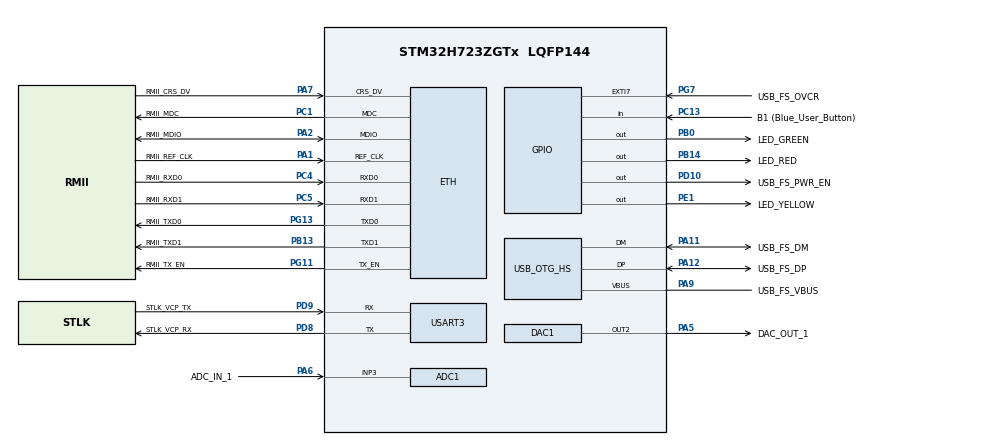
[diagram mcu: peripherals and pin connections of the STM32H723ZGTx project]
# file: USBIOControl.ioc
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ADC1.Channel-5\#ChannelRegularConversion=ADC_CHANNEL_3
ADC1.ClockPrescaler=ADC_CLOCK_ASYNC_DIV256
ADC1.ContinuousConvMode=ENABLE
ADC1.NbrOfConversion=1
ADC1.NbrOfConversionFlag=1
ADC1.OffsetNumber-5\#ChannelRegularConversion=ADC_OFFSET_NONE
ADC1.OffsetSignedSaturation-5\#ChannelRegularConversion=DISABLE
ADC1.Rank-5\#ChannelRegularConversion=1
ADC1.Resolution=ADC_RESOLUTION_12B
ADC1.SamplingTime-5\#ChannelRegularConversion=ADC_SAMPLETIME_1CYCLE_5
ADC1.master=1
DAC1.DAC_Channel-DAC_OUT2=DAC_CHANNEL_2
Dma.ADC1.0.Direction=DMA_PERIPH_TO_MEMORY
Dma.ADC1.0.EventEnable=DISABLE
Dma.ADC1.0.FIFOMode=DMA_FIFOMODE_DISABLE
Dma.ADC1.0.Instance=DMA1_Stream0
Dma.ADC1.0.MemDataAlignment=DMA_MDATAALIGN_HALFWORD
Dma.ADC1.0.MemInc=DMA_MINC_ENABLE
Dma.ADC1.0.Mode=DMA_CIRCULAR
Dma.ADC1.0.PeriphDataAlignment=DMA_PDATAALIGN_HALFWORD
Dma.ADC1.0.PeriphInc=DMA_PINC_DISABLE
Dma.ADC1.0.Polarity=HAL_DMAMUX_REQ_GEN_RISING
Dma.ADC1.0.Priority=DMA_PRIORITY_LOW
Dma.ADC1.0.RequestNumber=1
Dma.ADC1.0.SignalID=NONE
Dma.ADC1.0.SyncEnable=DISABLE
Dma.ADC1.0.SyncPolarity=HAL_DMAMUX_SYNC_NO_EVENT
Dma.ADC1.0.SyncRequestNumber=1
Dma.ADC1.0.SyncSignalID=NONE
Dma.Request0=ADC1
ETH.MediaInterface=HAL_ETH_RMII_MODE
Mcu.Family=STM32H7
Mcu.Name=STM32H723ZGTx
Mcu.Package=LQFP144
NVIC.DMA1_Stream0_IRQn=true\:0\:0\:false\:false\:true\:false\:true
NVIC.OTG_HS_IRQn=true\:0\:0\:false\:false\:true\:false\:true
NVIC.PriorityGroup=NVIC_PRIORITYGROUP_4
PA1.GPIO_Label=RMII_REF_CLK
PA1.Mode=RMII
PA1.Signal=ETH_REF_CLK
PA10.GPIO_Label=USB_FS_ID
PA10.Signal=USB_OTG_HS_ID
PA11.GPIO_Label=USB_FS_DM
PA11.Mode=Device_Only_FS
PA11.Signal=USB_OTG_HS_DM
PA12.GPIO_Label=USB_FS_DP
PA12.Mode=Device_Only_FS
PA12.Signal=USB_OTG_HS_DP
PA13(JTMS/SWDIO).GPIO_Label=SWDIO
PA13(JTMS/SWDIO).Mode=Trace_Asynchronous_SW
PA13(JTMS/SWDIO).Signal=DEBUG_JTMS-SWDIO
PA14(JTCK/SWCLK).GPIO_Label=SWCLK
PA14(JTCK/SWCLK).Mode=Trace_Asynchronous_SW
PA14(JTCK/SWCLK).Signal=DEBUG_JTCK-SWCLK
PA2.GPIO_Label=RMII_MDIO
PA2.Mode=RMII
PA2.Signal=ETH_MDIO
PA5.GPIO_Label=DAC_OUT_1
PA5.Signal=COMP_DAC12_group
PA6.GPIO_Label=ADC_IN_1
PA6.GPIO_Mode=GPIO_MODE_ANALOG
PA6.GPIO_PuPd=GPIO_NOPULL
PA6.Signal=ADCx_INP3
PA7.GPIO_Label=RMII_CRS_DV
PA7.Mode=RMII
PA7.Signal=ETH_CRS_DV
PA9.GPIO_Label=USB_FS_VBUS
PA9.Mode=Activate_VBUS_FS
PA9.Signal=USB_OTG_HS_VBUS
PB0.GPIO_Label=LED_GREEN
PB0.Signal=GPIO_Output
PB13.GPIO_Label=RMII_TXD1
PB13.Mode=RMII
PB13.Signal=ETH_TXD1
PB14.GPIO_Label=LED_RED
PB14.Signal=GPIO_Output
PB3(JTDO/TRACESWO).GPIO_Label=SWO
PB3(JTDO/TRACESWO).Mode=Trace_Asynchronous_SW
PB3(JTDO/TRACESWO).Signal=DEBUG_JTDO-SWO
PC1.GPIO_Label=RMII_MDC
PC1.Mode=RMII
PC1.Signal=ETH_MDC
PC13.GPIO_Label=B1 (Blue_User_Button)
PC13.Signal=GPIO_Input
PC14-OSC32_IN.Mode=LSE-External-Oscillator
PC14-OSC32_IN.Signal=RCC_OSC32_IN
PC15-OSC32_OUT.Mode=LSE-External-Oscillator
PC15-OSC32_OUT.Signal=RCC_OSC32_OUT
PC4.GPIO_Label=RMII_RXD0
PC4.Mode=RMII
PC4.Signal=ETH_RXD0
PC5.GPIO_Label=RMII_RXD1
PC5.Mode=RMII
PC5.Signal=ETH_RXD1
PD10.GPIO_Label=USB_FS_PWR_EN
PD10.Signal=GPIO_Output
PD8.GPIO_Label=STLK_VCP_RX
PD8.Mode=Asynchronous
PD8.Signal=USART3_TX
PD9.GPIO_Label=STLK_VCP_TX
PD9.Mode=Asynchronous
PD9.Signal=USART3_RX
PE1.GPIO_Label=LED_YELLOW
PE1.Signal=GPIO_Output
PG11.GPIO_Label=RMII_TX_EN
PG11.Mode=RMII
PG11.Signal=ETH_TX_EN
PG13.GPIO_Label=RMII_TXD0
PG13.Mode=RMII
PG13.Signal=ETH_TXD0
PG7.GPIO_Label=USB_FS_OVCR
PG7.Signal=GPXTI7
PH0-OSC_IN.GPIO_Label=MCO
PH0-OSC_IN.Mode=HSE-External-Clock-Source
PH0-OSC_IN.Signal=RCC_OSC_IN
PH1-OSC_OUT.Signal=RCC_OSC_OUT
ProjectManager.HeapSize=0x200
ProjectManager.StackSize=0x400
ProjectManager.TargetToolchain=STM32CubeIDE
RCC.ADCFreq_Value=96000000
RCC.APB1Freq_Value=137500000
RCC.APB2Freq_Value=137500000
RCC.APB3Freq_Value=137500000
RCC.APB4Freq_Value=137500000
RCC.CortexFreq_Value=550000000
RCC.D1PPRE=RCC_APB3_DIV2
RCC.D2PPRE1=RCC_APB1_DIV2
RCC.D2PPRE2=RCC_APB2_DIV2
RCC.D3PPRE=RCC_APB4_DIV2
RCC.DIVM1=4
RCC.DIVM2=1
RCC.DIVN1=275
RCC.DIVN2=24
RCC.DIVP1=1
RCC.DIVQ1=4
RCC.HCLKFreq_Value=275000000
RCC.HPRE=RCC_HCLK_DIV2
RCC.HSE_VALUE=8000000
RCC.PLLFRACN=0
RCC.PLLSourceVirtual=RCC_PLLSOURCE_HSE
RCC.SYSCLKFreq_VALUE=550000000
RCC.SYSCLKSource=RCC_SYSCLKSOURCE_PLLCLK
RCC.USBCLockSelection=RCC_USBCLKSOURCE_HSI48
RCC.USBFreq_Value=48000000
SH.ADCx_INP3.0=ADC1_INP3,IN3-Single-Ended
SH.COMP_DAC12_group.0=DAC1_OUT2,DAC_OUT2
USART3.VirtualMode-Asynchronous=VM_ASYNC
USB_DEVICE.CLASS_NAME_HS=CDC
USB_DEVICE.VirtualMode=Cdc
USB_DEVICE.VirtualModeHS=Cdc_HS
USB_OTG_HS.VirtualMode-Device_Only_FS=Device_Only_FS
VP_USB_DEVICE_VS_USB_DEVICE_CDC_HS.Mode=CDC_HS
board=NUCLEO-H723ZG

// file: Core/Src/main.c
/* USER CODE BEGIN Header */
/**
  ******************************************************************************
  * @file           : main.c
  * @brief          : Main program body
  ******************************************************************************
  * @attention
  *
  * Copyright (c) 2024 STMicroelectronics.
  * All rights reserved.
  *
  * This software is licensed under terms that can be found in the LICENSE file
  * in the root directory of this software component.
  * If no LICENSE file comes with this software, it is provided AS-IS.
  *
  ******************************************************************************
  */
/* USER CODE END Header */
#include "main.h"
#include "string.h"
#include "usb_device.h"

/* USER CODE BEGIN Includes */
#include "usbd_cdc_if.h"
#include <strings.h>
/* USER CODE END Includes */

#if defined ( __ICCARM__ ) /*!< IAR Compiler */

#pragma location=0x30000000
ETH_DMADescTypeDef  DMARxDscrTab[ETH_RX_DESC_CNT]; /* Ethernet Rx DMA Descriptors */
#pragma location=0x30000060
ETH_DMADescTypeDef  DMATxDscrTab[ETH_TX_DESC_CNT]; /* Ethernet Tx DMA Descriptors */
#pragma location=0x300000c0
uint8_t Rx_Buff[ETH_RX_DESC_CNT][ETH_MAX_PACKET_SIZE]; /* Ethernet Receive Buffers */

#elif defined ( __CC_ARM )  /* MDK ARM Compiler */

__attribute__((at(0x30000000))) ETH_DMADescTypeDef  DMARxDscrTab[ETH_RX_DESC_CNT]; /* Ethernet Rx DMA Descriptors */
__attribute__((at(0x30000060))) ETH_DMADescTypeDef  DMATxDscrTab[ETH_TX_DESC_CNT]; /* Ethernet Tx DMA Descriptors */
__attribute__((at(0x300000c0))) uint8_t Rx_Buff[ETH_RX_DESC_CNT][ETH_MAX_PACKET_SIZE]; /* Ethernet Receive Buffer */

#elif defined ( __GNUC__ ) /* GNU Compiler */

ETH_DMADescTypeDef DMARxDscrTab[ETH_RX_DESC_CNT] __attribute__((section(".RxDecripSection"))); /* Ethernet Rx DMA Descriptors */
ETH_DMADescTypeDef DMATxDscrTab[ETH_TX_DESC_CNT] __attribute__((section(".TxDecripSection")));   /* Ethernet Tx DMA Descriptors */
uint8_t Rx_Buff[ETH_RX_DESC_CNT][ETH_MAX_PACKET_SIZE] __attribute__((section(".RxArraySection"))); /* Ethernet Receive Buffers */

#endif

ETH_TxPacketConfig TxConfig;
ADC_HandleTypeDef hadc1;
DMA_HandleTypeDef hdma_adc1;

DAC_HandleTypeDef hdac1;

ETH_HandleTypeDef heth;

UART_HandleTypeDef huart3;

/* USER CODE BEGIN PV */
uint32_t value_adc;
uint32_t value_dac=0;
/* USER CODE END PV */

void SystemClock_Config(void);
static void MX_GPIO_Init(void);
static void MX_ETH_Init(void);
static void MX_USART3_UART_Init(void);
static void MX_DMA_Init(void);
static void MX_ADC1_Init(void);
static void MX_DAC1_Init(void);

/* USER CODE BEGIN 0 */
uint8_t data[6];
uint8_t buffer[64];
/* USER CODE END 0 */

int main(void)
{

  /* MCU Configuration--------------------------------------------------------*/

  /* Reset of all peripherals, Initializes the Flash interface and the Systick. */
  HAL_Init();

  /* Configure the system clock */
  SystemClock_Config();

  /* Initialize all configured peripherals */
  MX_GPIO_Init();
  MX_ETH_Init();
  MX_USART3_UART_Init();
  MX_DMA_Init();
  MX_ADC1_Init();
  MX_DAC1_Init();
  MX_USB_DEVICE_Init();
  /* USER CODE BEGIN 2 */

  HAL_DAC_Start(&hdac1,DAC_CHANNEL_2);
  HAL_ADCEx_Calibration_Start(&hadc1, ADC_CALIB_OFFSET_LINEARITY, ADC_SINGLE_ENDED);
  HAL_ADC_Start_DMA(&hadc1,(uint32_t*)&value_adc,1);
  /* USER CODE END 2 */

	data[0] = 0;
	data[1] = 0;
	data[2] = 0;
	data[3] = 0;
	data[4] = 0;
	data[5] = 10;

  /* Infinite loop */
  while (1)
  {
		HAL_GPIO_TogglePin(LED_GREEN_GPIO_Port, LED_GREEN_Pin);

		value_adc+=10;
itoa(value_adc, (char *) &data[0], 10);
		CDC_Transmit_HS(&data[0], sizeof(data));

		if(buffer[0]==1)
		{
			if(buffer[2] & (1u << 0))
			{
				HAL_GPIO_WritePin(LED_YELLOW_GPIO_Port, LED_YELLOW_Pin, GPIO_PIN_SET);
			}
			else
			{
				HAL_GPIO_WritePin(LED_YELLOW_GPIO_Port, LED_YELLOW_Pin, GPIO_PIN_RESET);
			}
			if(buffer[1] & (1u << 0))
			{
				HAL_GPIO_WritePin(LED_RED_GPIO_Port, LED_RED_Pin, GPIO_PIN_SET);
			}
			else
			{
				HAL_GPIO_WritePin(LED_RED_GPIO_Port, LED_RED_Pin, GPIO_PIN_RESET);
			}
//			value_dac = buffer[3]*10;
//			HAL_DAC_SetValue(&hdac1, DAC_CHANNEL_2, DAC_ALIGN_12B_R, value_dac);
		}

		HAL_DAC_SetValue(&hdac1, DAC_CHANNEL_2, DAC_ALIGN_12B_R, value_dac);

	  value_dac+=10;
	  if(value_dac>4095) {
		value_dac=0;
	  }

	  HAL_ADC_Start(&hadc1);
	  HAL_Delay(1000);
  }
}

void SystemClock_Config(void)
{
  RCC_OscInitTypeDef RCC_OscInitStruct = {0};
  RCC_ClkInitTypeDef RCC_ClkInitStruct = {0};

  /** Supply configuration update enable
  */
  HAL_PWREx_ConfigSupply(PWR_LDO_SUPPLY);
  /** Configure the main internal regulator output voltage
  */
  __HAL_PWR_VOLTAGESCALING_CONFIG(PWR_REGULATOR_VOLTAGE_SCALE0);

  while(!__HAL_PWR_GET_FLAG(PWR_FLAG_VOSRDY)) {}
  /** Macro to configure the PLL clock source
  */
  __HAL_RCC_PLL_PLLSOURCE_CONFIG(RCC_PLLSOURCE_HSE);
  /** Initializes the RCC Oscillators according to the specified parameters
  * in the RCC_OscInitTypeDef structure.
  */
  RCC_OscInitStruct.OscillatorType = RCC_OSCILLATORTYPE_HSI48|RCC_OSCILLATORTYPE_HSE;
  RCC_OscInitStruct.HSEState = RCC_HSE_BYPASS;
  RCC_OscInitStruct.HSI48State = RCC_HSI48_ON;
  RCC_OscInitStruct.PLL.PLLState = RCC_PLL_ON;
  RCC_OscInitStruct.PLL.PLLSource = RCC_PLLSOURCE_HSE;
  RCC_OscInitStruct.PLL.PLLM = 4;
  RCC_OscInitStruct.PLL.PLLN = 275;
  RCC_OscInitStruct.PLL.PLLP = 1;
  RCC_OscInitStruct.PLL.PLLQ = 4;
  RCC_OscInitStruct.PLL.PLLR = 2;
  RCC_OscInitStruct.PLL.PLLRGE = RCC_PLL1VCIRANGE_1;
  RCC_OscInitStruct.PLL.PLLVCOSEL = RCC_PLL1VCOWIDE;
  RCC_OscInitStruct.PLL.PLLFRACN = 0;
  if (HAL_RCC_OscConfig(&RCC_OscInitStruct) != HAL_OK)
  {
    Error_Handler();
  }
  /** Initializes the CPU, AHB and APB buses clocks
  */
  RCC_ClkInitStruct.ClockType = RCC_CLOCKTYPE_HCLK|RCC_CLOCKTYPE_SYSCLK
                              |RCC_CLOCKTYPE_PCLK1|RCC_CLOCKTYPE_PCLK2
                              |RCC_CLOCKTYPE_D3PCLK1|RCC_CLOCKTYPE_D1PCLK1;
  RCC_ClkInitStruct.SYSCLKSource = RCC_SYSCLKSOURCE_PLLCLK;
  RCC_ClkInitStruct.SYSCLKDivider = RCC_SYSCLK_DIV1;
  RCC_ClkInitStruct.AHBCLKDivider = RCC_HCLK_DIV2;
  RCC_ClkInitStruct.APB3CLKDivider = RCC_APB3_DIV2;
  RCC_ClkInitStruct.APB1CLKDivider = RCC_APB1_DIV2;
  RCC_ClkInitStruct.APB2CLKDivider = RCC_APB2_DIV2;
  RCC_ClkInitStruct.APB4CLKDivider = RCC_APB4_DIV2;

  if (HAL_RCC_ClockConfig(&RCC_ClkInitStruct, FLASH_LATENCY_3) != HAL_OK)
  {
    Error_Handler();
  }
}

static void MX_ADC1_Init(void)
{

  ADC_MultiModeTypeDef multimode = {0};
  ADC_ChannelConfTypeDef sConfig = {0};

  /** Common config
  */
  hadc1.Instance = ADC1;
  hadc1.Init.ClockPrescaler = ADC_CLOCK_ASYNC_DIV256;
  hadc1.Init.Resolution = ADC_RESOLUTION_12B;
  hadc1.Init.ScanConvMode = ADC_SCAN_DISABLE;
  hadc1.Init.EOCSelection = ADC_EOC_SINGLE_CONV;
  hadc1.Init.LowPowerAutoWait = DISABLE;
  hadc1.Init.ContinuousConvMode = ENABLE;
  hadc1.Init.NbrOfConversion = 1;
  hadc1.Init.DiscontinuousConvMode = DISABLE;
  hadc1.Init.ExternalTrigConv = ADC_SOFTWARE_START;
  hadc1.Init.ExternalTrigConvEdge = ADC_EXTERNALTRIGCONVEDGE_NONE;
  hadc1.Init.ConversionDataManagement = ADC_CONVERSIONDATA_DR;
  hadc1.Init.Overrun = ADC_OVR_DATA_PRESERVED;
  hadc1.Init.LeftBitShift = ADC_LEFTBITSHIFT_NONE;
  hadc1.Init.OversamplingMode = DISABLE;
  if (HAL_ADC_Init(&hadc1) != HAL_OK)
  {
    Error_Handler();
  }
  /** Configure the ADC multi-mode
  */
  multimode.Mode = ADC_MODE_INDEPENDENT;
  if (HAL_ADCEx_MultiModeConfigChannel(&hadc1, &multimode) != HAL_OK)
  {
    Error_Handler();
  }
  /** Configure Regular Channel
  */
  sConfig.Channel = ADC_CHANNEL_3;
  sConfig.Rank = ADC_REGULAR_RANK_1;
  sConfig.SamplingTime = ADC_SAMPLETIME_1CYCLE_5;
  sConfig.SingleDiff = ADC_SINGLE_ENDED;
  sConfig.OffsetNumber = ADC_OFFSET_NONE;
  sConfig.Offset = 0;
  sConfig.OffsetSignedSaturation = DISABLE;
  if (HAL_ADC_ConfigChannel(&hadc1, &sConfig) != HAL_OK)
  {
    Error_Handler();
  }

}

static void MX_DAC1_Init(void)
{

  DAC_ChannelConfTypeDef sConfig = {0};

  /** DAC Initialization
  */
  hdac1.Instance = DAC1;
  if (HAL_DAC_Init(&hdac1) != HAL_OK)
  {
    Error_Handler();
  }
  /** DAC channel OUT2 config
  */
  sConfig.DAC_SampleAndHold = DAC_SAMPLEANDHOLD_DISABLE;
  sConfig.DAC_Trigger = DAC_TRIGGER_NONE;
  sConfig.DAC_OutputBuffer = DAC_OUTPUTBUFFER_ENABLE;
  sConfig.DAC_ConnectOnChipPeripheral = DAC_CHIPCONNECT_DISABLE;
  sConfig.DAC_UserTrimming = DAC_TRIMMING_FACTORY;
  if (HAL_DAC_ConfigChannel(&hdac1, &sConfig, DAC_CHANNEL_2) != HAL_OK)
  {
    Error_Handler();
  }

}

static void MX_ETH_Init(void)
{

   static uint8_t MACAddr[6];

  heth.Instance = ETH;
  MACAddr[0] = 0x00;
  MACAddr[1] = 0x80;
  MACAddr[2] = 0xE1;
  MACAddr[3] = 0x00;
  MACAddr[4] = 0x00;
  MACAddr[5] = 0x00;
  heth.Init.MACAddr = &MACAddr[0];
  heth.Init.MediaInterface = HAL_ETH_RMII_MODE;
  heth.Init.TxDesc = DMATxDscrTab;
  heth.Init.RxDesc = DMARxDscrTab;
  heth.Init.RxBuffLen = 1524;

  if (HAL_ETH_Init(&heth) != HAL_OK)
  {
    Error_Handler();
  }

  memset(&TxConfig, 0 , sizeof(ETH_TxPacketConfig));
  TxConfig.Attributes = ETH_TX_PACKETS_FEATURES_CSUM | ETH_TX_PACKETS_FEATURES_CRCPAD;
  TxConfig.ChecksumCtrl = ETH_CHECKSUM_IPHDR_PAYLOAD_INSERT_PHDR_CALC;
  TxConfig.CRCPadCtrl = ETH_CRC_PAD_INSERT;

}

static void MX_USART3_UART_Init(void)
{

  huart3.Instance = USART3;
  huart3.Init.BaudRate = 115200;
  huart3.Init.WordLength = UART_WORDLENGTH_8B;
  huart3.Init.StopBits = UART_STOPBITS_1;
  huart3.Init.Parity = UART_PARITY_NONE;
  huart3.Init.Mode = UART_MODE_TX_RX;
  huart3.Init.HwFlowCtl = UART_HWCONTROL_NONE;
  huart3.Init.OverSampling = UART_OVERSAMPLING_16;
  huart3.Init.OneBitSampling = UART_ONE_BIT_SAMPLE_DISABLE;
  huart3.Init.ClockPrescaler = UART_PRESCALER_DIV1;
  huart3.AdvancedInit.AdvFeatureInit = UART_ADVFEATURE_NO_INIT;
  if (HAL_UART_Init(&huart3) != HAL_OK)
  {
    Error_Handler();
  }
  if (HAL_UARTEx_SetTxFifoThreshold(&huart3, UART_TXFIFO_THRESHOLD_1_8) != HAL_OK)
  {
    Error_Handler();
  }
  if (HAL_UARTEx_SetRxFifoThreshold(&huart3, UART_RXFIFO_THRESHOLD_1_8) != HAL_OK)
  {
    Error_Handler();
  }
  if (HAL_UARTEx_DisableFifoMode(&huart3) != HAL_OK)
  {
    Error_Handler();
  }

}

static void MX_DMA_Init(void)
{

  /* DMA controller clock enable */
  __HAL_RCC_DMA1_CLK_ENABLE();

  /* DMA interrupt init */
  /* DMA1_Stream0_IRQn interrupt configuration */
  HAL_NVIC_SetPriority(DMA1_Stream0_IRQn, 0, 0);
  HAL_NVIC_EnableIRQ(DMA1_Stream0_IRQn);

}

static void MX_GPIO_Init(void)
{
  GPIO_InitTypeDef GPIO_InitStruct = {0};

  /* GPIO Ports Clock Enable */
  __HAL_RCC_GPIOC_CLK_ENABLE();
  __HAL_RCC_GPIOH_CLK_ENABLE();
  __HAL_RCC_GPIOA_CLK_ENABLE();
  __HAL_RCC_GPIOB_CLK_ENABLE();
  __HAL_RCC_GPIOD_CLK_ENABLE();
  __HAL_RCC_GPIOG_CLK_ENABLE();
  __HAL_RCC_GPIOE_CLK_ENABLE();

  /*Configure GPIO pin Output Level */
  HAL_GPIO_WritePin(GPIOB, LED_GREEN_Pin|LED_RED_Pin, GPIO_PIN_RESET);

  /*Configure GPIO pin Output Level */
  HAL_GPIO_WritePin(USB_FS_PWR_EN_GPIO_Port, USB_FS_PWR_EN_Pin, GPIO_PIN_RESET);

  /*Configure GPIO pin Output Level */
  HAL_GPIO_WritePin(LED_YELLOW_GPIO_Port, LED_YELLOW_Pin, GPIO_PIN_RESET);

  /*Configure GPIO pin : B1_Pin */
  GPIO_InitStruct.Pin = B1_Pin;
  GPIO_InitStruct.Mode = GPIO_MODE_INPUT;
  GPIO_InitStruct.Pull = GPIO_NOPULL;
  HAL_GPIO_Init(B1_GPIO_Port, &GPIO_InitStruct);

  /*Configure GPIO pins : LED_GREEN_Pin LED_RED_Pin */
  GPIO_InitStruct.Pin = LED_GREEN_Pin|LED_RED_Pin;
  GPIO_InitStruct.Mode = GPIO_MODE_OUTPUT_PP;
  GPIO_InitStruct.Pull = GPIO_NOPULL;
  GPIO_InitStruct.Speed = GPIO_SPEED_FREQ_LOW;
  HAL_GPIO_Init(GPIOB, &GPIO_InitStruct);

  /*Configure GPIO pin : USB_FS_PWR_EN_Pin */
  GPIO_InitStruct.Pin = USB_FS_PWR_EN_Pin;
  GPIO_InitStruct.Mode = GPIO_MODE_OUTPUT_PP;
  GPIO_InitStruct.Pull = GPIO_NOPULL;
  GPIO_InitStruct.Speed = GPIO_SPEED_FREQ_LOW;
  HAL_GPIO_Init(USB_FS_PWR_EN_GPIO_Port, &GPIO_InitStruct);

  /*Configure GPIO pin : USB_FS_OVCR_Pin */
  GPIO_InitStruct.Pin = USB_FS_OVCR_Pin;
  GPIO_InitStruct.Mode = GPIO_MODE_IT_RISING;
  GPIO_InitStruct.Pull = GPIO_NOPULL;
  HAL_GPIO_Init(USB_FS_OVCR_GPIO_Port, &GPIO_InitStruct);

  /*Configure GPIO pin : LED_YELLOW_Pin */
  GPIO_InitStruct.Pin = LED_YELLOW_Pin;
  GPIO_InitStruct.Mode = GPIO_MODE_OUTPUT_PP;
  GPIO_InitStruct.Pull = GPIO_NOPULL;
  GPIO_InitStruct.Speed = GPIO_SPEED_FREQ_LOW;
  HAL_GPIO_Init(LED_YELLOW_GPIO_Port, &GPIO_InitStruct);

}

void Error_Handler(void)
{
  __disable_irq();
  while (1)
  {
  }
}
